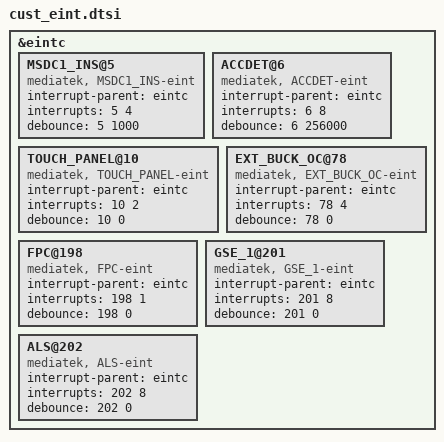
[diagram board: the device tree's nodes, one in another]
/*
 * Generated by MTK SP DrvGen Version 03.13.6 for MT6753. Copyright MediaTek Inc. (C) 2013.
 * Wed Oct 28 16:27:33 2015
 * Do Not Modify the File.
 */

/*************************
 * EINT DTSI File
*************************/

&eintc {
	MSDC1_INS@5 {
		compatible = "mediatek, MSDC1_INS-eint";
		interrupt-parent = <&eintc>;
		interrupts = <5 4>;
		debounce = <5 1000>;
	};

	ACCDET@6 {
		compatible = "mediatek, ACCDET-eint";
		interrupt-parent = <&eintc>;
		interrupts = <6 8>;
		debounce = <6 256000>;
	};

	TOUCH_PANEL@10 {
		compatible = "mediatek, TOUCH_PANEL-eint";
		interrupt-parent = <&eintc>;
		interrupts = <10 2>;
		debounce = <10 0>;
	};

	EXT_BUCK_OC@78 {
		compatible = "mediatek, EXT_BUCK_OC-eint";
		interrupt-parent = <&eintc>;
		interrupts = <78 4>;
		debounce = <78 0>;
	};

	FPC@198 {
		compatible = "mediatek, FPC-eint";
		interrupt-parent = <&eintc>;
		interrupts = <198 1>;
		debounce = <198 0>;
	};

	GSE_1@201 {
		compatible = "mediatek, GSE_1-eint";
		interrupt-parent = <&eintc>;
		interrupts = <201 8>;
		debounce = <201 0>;
	};

	ALS@202 {
		compatible = "mediatek, ALS-eint";
		interrupt-parent = <&eintc>;
		interrupts = <202 8>;
		debounce = <202 0>;
	};

};
